# RTS5918 register map
Vendor: Realtek Semiconductor Corp.; Series: RTS5918 Series; File version: 1.00
CPU: ARMV8MML r0p0, little endian, MPU, FPU, VTOR, 3 interrupt priority bits, 8 SAU regions
Registers are 32-bit, read-write, reset 0x0 unless marked. A register's access mark holds for its fields unless they carry their own. Offsets are from the block's base; [hi:lo] are bit positions; {n}, {i} and the like mark numbered series; 'fields as' and 'values as' point back to an identical list.

## SPIM — SPIM Controller
Base 0x40221B00
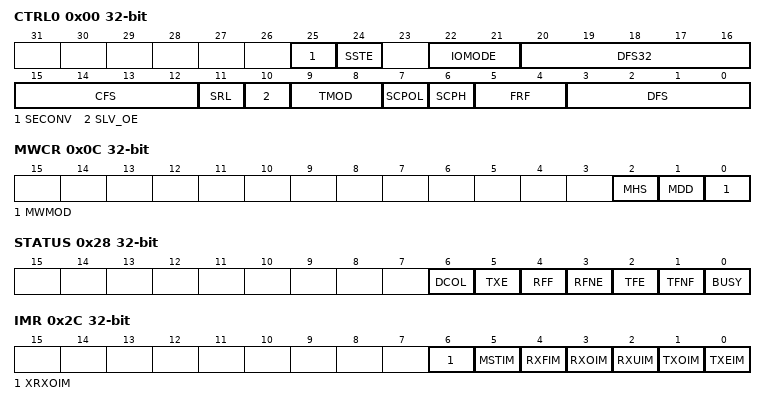
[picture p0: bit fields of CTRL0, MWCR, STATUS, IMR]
0x00 CTRL0 — SPIM CONTROL 0 REGISTER
  [25] SECONV — Set the Endianness for XIP and data register reads
    0=NORMAL (Normal Mode Operation); 1=TESTING (Test Mode Operation)
  [24] SSTE — Slave Select Toggle Enable
  [22:21] IOMODE
    0=SINGLE (Single Mode); 1=DUAL (Dual Mode); 2=QUAD (QUAD Mode); 3=OCTAL (OCTAL Mode)
  [20:16] DFS32 — Data Frame Size
  [15:12] CFS — Control Frame Size
  [11] SRL — Shift Register Loop
    values as SECONV
  [10] SLV_OE — Slave Output Enable
    0=ENABLE (Slave Output is Disabled); 1=DISABLE (Slave Output is Eabled)
  [9:8] TMOD — Transfer Mode
    0=TX_AND_RX (Transmit and Receive); 1=TX_ONLY (Transmit only mode); 2=RX_AND_RX (Receive only mode); 3=EEPROM_READ (EEPROM Read mode)
  [7] SCPOL — Serial Clock Polarity
    0=HIGH (Inactive State of Serial Clock is High); 1=LOW (Inactive State of Serial Clock is Low)
  [6] SCPH — Serial Clock Phase
    0=MIDDLE (Serial Clock Toggles in Middle of First Bit); 1=START (Serial Clock Toggles at Start of First Bit)
  [5:4] FRF — Frame Format
    0=SPI (Motorola SPI Frame Format); 1=SSP (Texas Instruments SSP Frame Format); 2=MICROWIRE (National Semiconductors Microwire Frame Format)
  [3:0] DFS — Data Frame Size
0x04 CTRLR1 — SPIM CONTROL 1 REGISTER
  [15:0] NDF — Number of Data Frames
0x08 SPIENR — SPI ENABLE REGISTER
  [0] EN — SPI Maste Enable Bit
    0=DISABLE (Disable SPIM); 1=ENABLE (Enable SPIM)
0x0C MWCR — Microwire Control Register
  [2] MHS — Microwire Handshaking
    0=DISABLE (Disable Handshaking); 1=ENABLE (Enable Handshaking)
  [1] MDD ro — Microwire Control
    0=RX (Receives Data); 1=TX (Transmits Data)
  [0] MWMOD — Microwire Transfer Sequentail Mode
    0=DISABLE (Disable Sequential Mode); 1=ENABLE (Enable Sequential Mode)
0x10 SER — SLAVE ENABLE REGISTER
0x14 BAUDR — BAUD RATE SELECT REGISTER
  [15:0] SCKDV — Clock Divider
0x18 TXFTLR — TX THRESHOLD REGISTER
0x1C RXFTLR — RX THRESHOLD REGISTER
0x20 TXFLR ro — TX FIFO LEVEL REGISTER
0x24 RXFLR ro — RX FIFO LEVEL REGISTER
0x28 STATUS ro
  [6] DCOL — Data Collision Error
  [5] TXE — Transmission Error
  [4] RFF — Receive FIFO Full
  [3] RFNE — Receive FIFO Not Empty
  [2] TFE — Transmit FIFO Empty
  [1] TFNF — Transmit FIFO Not Full
  [0] BUSY — Busy Flag
0x2C IMR — INTERRUPT MASK REGISTER
  [6] XRXOIM — XIP Receive FIFO Overflow Interrupt Mask
  [5] MSTIM — Multi-Master Contention Interrupt Mask
  [4] RXFIM — Receive FIFO Full Interrupt Mask 0
  [3] RXOIM — Receive FIFO Overflow Interrupt Mask
  [2] RXUIM — Receive FIFO Underflow Interrupt Mask
  [1] TXOIM — Transmit FIFO Overflow Interrupt Mask
  [0] TXEIM — Transmit FIFO Empty Interrupt Mask
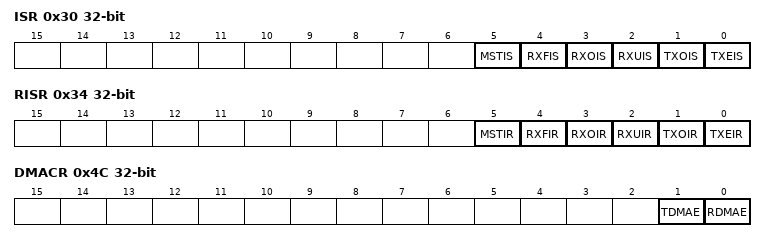
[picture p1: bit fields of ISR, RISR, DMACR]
0x30 ISR ro — INTERRUPT STATUS REGISTER
  [5] MSTIS — Multi-Master Contention Interrupt Status
  [4] RXFIS — Receive FIFO Full Interrupt Status
  [3] RXOIS — Receive FIFO Overflow Interrupt Status
  [2] RXUIS — Receive FIFO Underflow Interrupt Status
  [1] TXOIS — Transmit FIFO Overflow Interrupt Status
  [0] TXEIS — Transmit FIFO Empty Interrupt Status
0x34 RISR ro — INTERRUPT STATUS REGISTER
  [5] MSTIR — Multi-Master Contention Raw Interrupt Status
  [4] RXFIR — Receive FIFO Full Raw Interrupt Status
  [3] RXOIR — Receive FIFO Overflow Raw Interrupt Status
  [2] RXUIR — Receive FIFO Underflow Raw Interrupt Status
  [1] TXOIR — Transmit FIFO Overflow Raw Interrupt Status
  [0] TXEIR — Transmit FIFO Empty Raw Interrupt Status
0x38 TXOICR ro — Transmit FIFO Overflow Interrupt Clear Register
  [0] CLEAR — Clear Interrupt
0x3C RXOICR ro — Receive FIFO Overflow Interrupt Clear Register
  [0] CLEAR — Clear Interrupt
0x40 RXUICR ro — Receive FIFO Underflow Interrupt Clear Register
  [0] CLEAR — Clear Interrupt
0x44 MSTICR ro — Multi-Master Interrupt Clear Register
  [0] CLEAR — Clear Interrupt
0x48 ICR ro — Interrupt Clear Register
  [0] CLEAR — Clear Interrupt
0x4C DMACR — DMA Control Register
  [1] TDMAE — Transmit DMA Enable
  [0] RDMAE — Receive DMA Enable
0x50 DMATDLR — DMA Transmit Data Level Register
0x54 DMARDLR — DMA Receive Data Level Register
{0x60+4i} DATA[{i}] (i=0..35)
